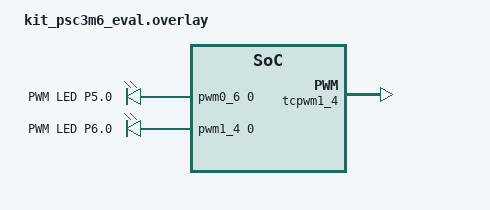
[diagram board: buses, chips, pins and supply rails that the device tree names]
/*
 * SPDX-FileCopyrightText: Copyright (c) 2026 Infineon Technologies AG,
 * SPDX-FileCopyrightText: or an affiliate of Infineon Technologies AG. All rights reserved.
 *
 * SPDX-License-Identifier: Apache-2.0
 */

#include <zephyr/dt-bindings/pwm/pwm.h>
#include <zephyr/dt-bindings/pwm/pwm_ifx_tcpwm.h>

/*
 * The PSC3M6 only outputs some of the PWM devices to pins using the pin control driver.  None of
 * the PWM-Pin combinations available are tied to an LED on this board, so for this demonstration
 * we are using GPIO pins as the output of the PWM.  These can be connected to an external LED by
 * the user or observed on an oscilloscope.
 *
 * The PSC3 family allows any PWM output to be routed to any pin using the Trigger Mux functionality
 * of the part.  Once Zephyr support for the trigger mux configuration has been enabled this sample
 * will be updated to use the on-board LEDs.
 */

/ {
	aliases {
		pwm-led0 = &pwm_led0;
		pwm-led1 = &pwm_led1;
	};

	pwmleds {
		compatible = "pwm-leds";

		pwm_led0: pwm_led_0 {
			pwms = <&pwm0_6 0 PWM_MSEC(20) PWM_POLARITY_INVERTED>;
			label = "PWM LED P5.0";
		};

		pwm_led1: pwm_led_1 {
			pwms = <&pwm1_4 0 PWM_MSEC(20) PWM_POLARITY_NORMAL>;
			label = "PWM LED P6.0";
		};
	};
};

/* Second channel reuses the peripheral clock divider already set up by the board. */
&tcpwm1_4 {
	status = "okay";

	pwm1_4: pwm1_4 {
		status = "okay";
		clocks = <&peri0_group0_16bit_2>;
		pinctrl-0 = <&p6_0_pwm1_4>;
		pinctrl-names = "default";
	};
};

&pinctrl {
	p6_0_pwm1_4: p6_0_pwm1_4 {
		drive-push-pull;
	};
};
